# MKW20Z4 register map
Vendor: Freescale Semiconductor, Inc.; Series: Kinetis_W; File version: 1.6
CPU: CM0PLUS r0p0, little endian, no MPU, no FPU, VTOR, 2 interrupt priority bits
Registers are 32-bit, read-write, reset 0x0 unless marked. A register's access mark holds for its fields unless they carry their own. Offsets are from the block's base; [hi:lo] are bit positions; lines under a group give offsets from that group; {n}, {i} and the like mark numbered series.

## XCVR (part 2 of 2) — Apache 1.0 Transceiver
Base 0x4005C000; register names take the prefix XCVR_
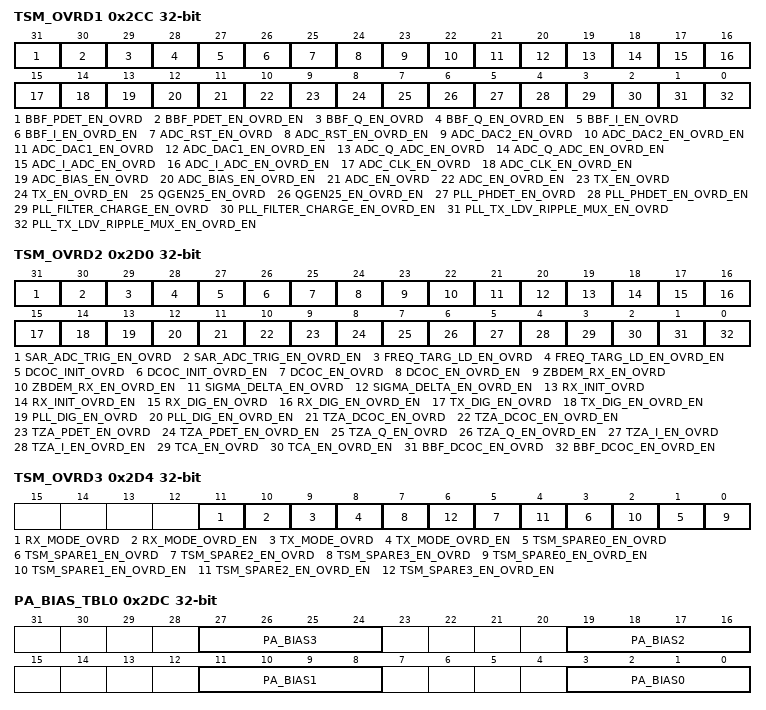
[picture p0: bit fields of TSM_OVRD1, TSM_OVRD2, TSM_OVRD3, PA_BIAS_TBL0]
0x2CC TSM_OVRD1 — TSM Override 1
  [31] BBF_PDET_EN_OVRD — Override value for BBF_PDET_EN
  [30] BBF_PDET_EN_OVRD_EN — Override control for BBF_PDET_EN
    0=Normal operation; 1=Use the state of BBF_PDET_EN_OVRD to override the signal "bbf_pdet_en"
  [29] BBF_Q_EN_OVRD — Override value for BBF_Q_EN
  [28] BBF_Q_EN_OVRD_EN — Override control for BBF_Q_EN
    0=Normal operation; 1=Use the state of BBF_Q_EN_OVRD to override the signal "bbf_q_en"
  [27] BBF_I_EN_OVRD — Override value for BBF_I_EN
  [26] BBF_I_EN_OVRD_EN — Override control for BBF_I_EN
    0=Normal operation; 1=Use the state of BBF_I_EN_OVRD to override the signal "bbf_i_en"
  [25] ADC_RST_EN_OVRD — Override value for ADC_RST_EN
  [24] ADC_RST_EN_OVRD_EN — Override control for ADC_RST_EN
    0=Normal operation; 1=Use the state of ADC_RST_EN_OVRD to override the signal "adc_rst_en"
  [23] ADC_DAC2_EN_OVRD — Override value for ADC_DAC2_EN
  [22] ADC_DAC2_EN_OVRD_EN — Override control for ADC_DAC2_EN
    0=Normal operation; 1=Use the state of ADC_DAC2_EN_OVRD to override the signal "adc_dac2_en"
  [21] ADC_DAC1_EN_OVRD — Override value for ADC_DAC1_EN
  [20] ADC_DAC1_EN_OVRD_EN — Override control for ADC_DAC1_EN
    0=Normal operation; 1=Use the state of ADC_DAC1_EN_OVRD to override the signal "adc_dac1_en"
  [19] ADC_Q_ADC_EN_OVRD — Override value for ADC_Q_ADC_EN
  [18] ADC_Q_ADC_EN_OVRD_EN — Override control for ADC_Q_ADC_EN
    0=Normal operation; 1=Use the state of ADC_Q_ADC_EN_OVRD to override the signal "adc_q_adc_en"
  [17] ADC_I_ADC_EN_OVRD — Override value for ADC_I_ADC_EN
  [16] ADC_I_ADC_EN_OVRD_EN — Override control for ADC_I_ADC_EN
    0=Normal operation; 1=Use the state of ADC_I_ADC_EN_OVRD to override the signal "adc_i_adc_en"
  [15] ADC_CLK_EN_OVRD — Override value for ADC_CLK_EN
  [14] ADC_CLK_EN_OVRD_EN — Override control for ADC_CLK_EN
    0=Normal operation; 1=Use the state of ADC_CLK_EN_OVRD to override the signal "adc_clk_en"
  [13] ADC_BIAS_EN_OVRD — Override value for ADC_BIAS_EN
  [12] ADC_BIAS_EN_OVRD_EN — Override control for ADC_BIAS_EN
    0=Normal operation; 1=Use the state of ADC_BIAS_EN_OVRD to override the signal "adc_bias_en"
  [11] ADC_EN_OVRD — Override value for ADC_EN
  [10] ADC_EN_OVRD_EN — Override control for ADC_EN
    0=Normal operation; 1=Use the state of ADC_EN_OVRD to override the signal "adc_en"
  [9] TX_EN_OVRD — Override value for TX_EN
  [8] TX_EN_OVRD_EN — Override control for TX_EN
    0=Normal operation; 1=Use the state of TX_EN_OVRD to override the signal "tx_en"
  [7] QGEN25_EN_OVRD — Override value for QGEN25_EN
  [6] QGEN25_EN_OVRD_EN — Override control for QGEN25_EN
    0=Normal operation; 1=Use the state of QGEN25_EN_OVRD to override the signal "qgen25_en"
  [5] PLL_PHDET_EN_OVRD — Override value for PLL_PHDET_EN
  [4] PLL_PHDET_EN_OVRD_EN — Override control for PLL_PHDET_EN
    0=Normal operation; 1=Use the state of PLL_PHDET_EN_OVRD to override the signal "pll_phdet_en"
  [3] PLL_FILTER_CHARGE_EN_OVRD — Override value for PLL_FILTER_CHARGE_EN
  [2] PLL_FILTER_CHARGE_EN_OVRD_EN — Override control for PLL_FILTER_CHARGE_EN
    0=Normal operation; 1=Use the state of PLL_FILTER_CHARGE_EN_OVRD to override the signal "pll_filter_charge_en"
  [1] PLL_TX_LDV_RIPPLE_MUX_EN_OVRD — Override value for PLL_TX_LDV_RIPPLE_MUX_EN
  [0] PLL_TX_LDV_RIPPLE_MUX_EN_OVRD_EN — Override control for PLL_TX_LDV_RIPPLE_MUX_EN
    0=Normal operation; 1=Use the state of PLL_TX_LDV_RIPPLE_MUX_EN_OVRD to override the signal "pll_tx_ldv_ripple_mux_en"
0x2D0 TSM_OVRD2 — TSM Override 2
  [31] SAR_ADC_TRIG_EN_OVRD — Override value for SAR_ADC_TRIG_EN
  [30] SAR_ADC_TRIG_EN_OVRD_EN — Override control for SAR_ADC_TRIG_EN
    0=Normal operation; 1=Use the state of SAR_ADC_TRIG_EN_OVRD to override the signal "sar_adc_trig_en"
  [29] FREQ_TARG_LD_EN_OVRD — Override value for FREQ_TARG_LD_EN
  [28] FREQ_TARG_LD_EN_OVRD_EN — Override control for FREQ_TARG_LD_EN
    0=Normal operation; 1=Use the state of FREQ_TARG_LD_EN_OVRD to override the signal "freq_targ_ld_en"
  [27] DCOC_INIT_OVRD — Override value for DCOC_INIT
  [26] DCOC_INIT_OVRD_EN — Override control for DCOC_INIT
    0=Normal operation; 1=Use the state of DCOC_INIT_OVRD to override the signal "dcoc_init"
  [25] DCOC_EN_OVRD — Override value for DCOC_EN
  [24] DCOC_EN_OVRD_EN — Override control for DCOC_EN
    0=Normal operation; 1=Use the state of DCOC_EN_OVRD to override the signal "dcoc_en"
  [23] ZBDEM_RX_EN_OVRD — Override value for ZBDEM_RX_EN
  [22] ZBDEM_RX_EN_OVRD_EN — Override control for ZBDEM_RX_EN
    0=Normal operation; 1=Use the state of ZBDEM_RX_EN_OVRD to override the signal "zbdem_rx_en"
  [21] SIGMA_DELTA_EN_OVRD — Override value for SIGMA_DELTA_EN
  [20] SIGMA_DELTA_EN_OVRD_EN — Override control for SIGMA_DELTA_EN
    0=Normal operation; 1=Use the state of SIGMA_DELTA_EN_OVRD to override the signal "sigma_delta_en"
  [19] RX_INIT_OVRD — Override value for RX_INIT
  [18] RX_INIT_OVRD_EN — Override control for RX_INIT
    0=Normal operation; 1=Use the state of RX_INIT_OVRD to override the signal "rx_init"
  [17] RX_DIG_EN_OVRD — Override value for RX_DIG_EN
  [16] RX_DIG_EN_OVRD_EN — Override control for RX_DIG_EN
    0=Normal operation; 1=Use the state of RX_DIG_EN_OVRD to override the signal "rx_dig_en"
  [15] TX_DIG_EN_OVRD — Override value for TX_DIG_EN
  [14] TX_DIG_EN_OVRD_EN — Override control for TX_DIG_EN
    0=Normal operation; 1=Use the state of TX_DIG_EN_OVRD to override the signal "tx_dig_en"
  [13] PLL_DIG_EN_OVRD — Override value for PLL_DIG_EN
  [12] PLL_DIG_EN_OVRD_EN — Override control for PLL_DIG_EN
    0=Normal operation; 1=Use the state of PLL_DIG_EN_OVRD to override the signal "pll_dig_en"
  [11] TZA_DCOC_EN_OVRD — Override value for TZA_DCOC_EN
  [10] TZA_DCOC_EN_OVRD_EN — Override control for TZA_DCOC_EN
    0=Normal operation; 1=Use the state of TZA_DCOC_EN_OVRD to override the signal "tza_dcoc_en"
  [9] TZA_PDET_EN_OVRD — Override value for TZA_PDET_EN
  [8] TZA_PDET_EN_OVRD_EN — Override control for TZA_PDET_EN
    0=Normal operation; 1=Use the state of TZA_PDET_EN_OVRD to override the signal "tza_pdet_en"
  [7] TZA_Q_EN_OVRD — Override value for TZA_Q_EN
  [6] TZA_Q_EN_OVRD_EN — Override control for TZA_Q_EN
    0=Normal operation; 1=Use the state of TZA_Q_EN_OVRD to override the signal "tza_q_en"
  [5] TZA_I_EN_OVRD — Override value for TZA_I_EN
  [4] TZA_I_EN_OVRD_EN — Override control for TZA_I_EN
    0=Normal operation; 1=Use the state of TZA_I_EN_OVRD to override the signal "tza_i_en"
  [3] TCA_EN_OVRD — Override value for TCA_EN
  [2] TCA_EN_OVRD_EN — Override control for TCA_EN
    0=Normal operation; 1=Use the state of TCA_EN_OVRD to override the signal "tca_en"
  [1] BBF_DCOC_EN_OVRD — Override value for BBF_DCOC_EN
  [0] BBF_DCOC_EN_OVRD_EN — Override control for BBF_DCOC_EN
    0=Normal operation; 1=Use the state of BBF_DCOC_EN_OVRD to override the signal "bbf_dcoc_en"
0x2D4 TSM_OVRD3 — TSM Override 3
  [11] RX_MODE_OVRD — Override value for RX_MODE
  [10] RX_MODE_OVRD_EN — Override control for RX_MODE
    0=Normal operation; 1=Use the state of RX_MODE_OVRD to override the signal "rx_mode"
  [9] TX_MODE_OVRD — Override value for TX_MODE
  [8] TX_MODE_OVRD_EN — Override control for TX_MODE
    0=Normal operation; 1=Use the state of TX_MODE_OVRD to override the signal "tx_mode"
  [2n+1] TSM_SPARE{n}_EN_OVRD (n=0..3) — Override value for TSM_SPARE{n}_EN
  [2n] TSM_SPARE{n}_EN_OVRD_EN (n=0..3) — Override control for TSM_SPARE{n}_EN
    0=Normal operation; 1=Use the state of TSM_SPARE{n}_EN_OVRD to override the signal "tsm_spare{n}_en"
0x2D8 PA_POWER
  [3:0] PA_POWER
0x2DC PA_BIAS_TBL0 — PA Bias Table 0
  [8n+3:8n] PA_BIAS{n} (n=0..3)
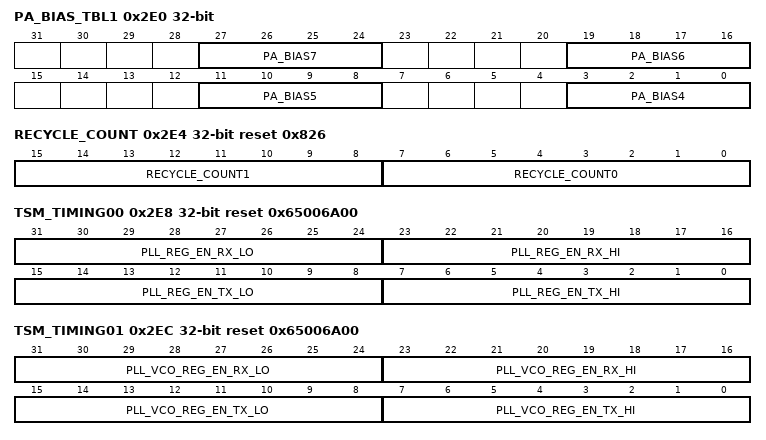
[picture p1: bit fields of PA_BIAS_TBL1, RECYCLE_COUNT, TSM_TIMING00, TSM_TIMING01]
0x2E0 PA_BIAS_TBL1 — PA Bias Table 1
  [8n-29:8n-32] PA_BIAS{n} (n=4..7)
0x2E4 RECYCLE_COUNT reset 0x826
  [15:8] RECYCLE_COUNT1 — TSM RX Recycle Count 1
  [7:0] RECYCLE_COUNT0 — TSM RX Recycle Count 0
0x2E8 TSM_TIMING00 reset 0x65006A00
  [31:24] PLL_REG_EN_RX_LO — Deassertion time setting for PLL_REG_EN signal or group RX sequence.
  [23:16] PLL_REG_EN_RX_HI — Assertion time setting for PLL_REG_EN signal or group RX sequence.
  [15:8] PLL_REG_EN_TX_LO — Deassertion time setting for PLL_REG_EN signal or group TX sequence.
  [7:0] PLL_REG_EN_TX_HI — Assertion time setting for PLL_REG_EN TX sequence.
0x2EC TSM_TIMING01 reset 0x65006A00
  [31:24] PLL_VCO_REG_EN_RX_LO — Deassertion time setting for PLL_VCO_REG_EN signal or group RX sequence.
  [23:16] PLL_VCO_REG_EN_RX_HI — Assertion time setting for PLL_VCO_REG_EN signal or group RX sequence.
  [15:8] PLL_VCO_REG_EN_TX_LO — Deassertion time setting for PLL_VCO_REG_EN signal or group TX sequence.
  [7:0] PLL_VCO_REG_EN_TX_HI — Assertion time setting for PLL_VCO_REG_EN TX sequence.
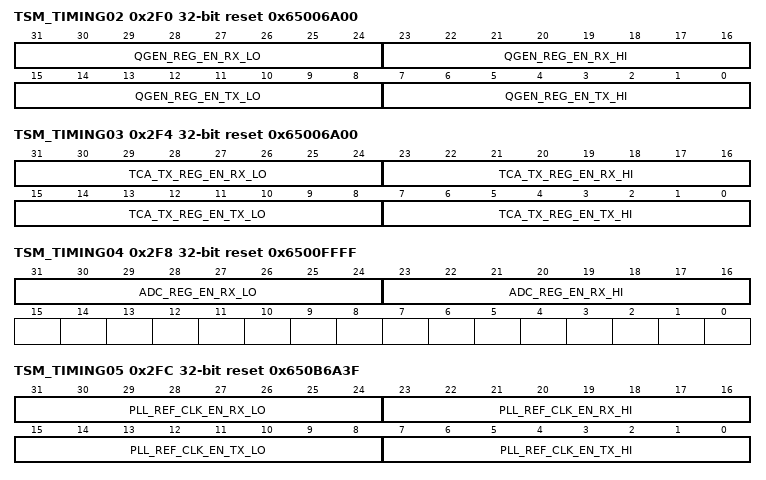
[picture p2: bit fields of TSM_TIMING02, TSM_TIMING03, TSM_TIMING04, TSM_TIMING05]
0x2F0 TSM_TIMING02 reset 0x65006A00
  [31:24] QGEN_REG_EN_RX_LO — Deassertion time setting for QGEN_REG_EN signal or group RX sequence.
  [23:16] QGEN_REG_EN_RX_HI — Assertion time setting for QGEN_REG_EN signal or group RX sequence.
  [15:8] QGEN_REG_EN_TX_LO — Deassertion time setting for QGEN_REG_EN signal or group TX sequence.
  [7:0] QGEN_REG_EN_TX_HI — Assertion time setting for QGEN_REG_EN TX sequence.
0x2F4 TSM_TIMING03 reset 0x65006A00
  [31:24] TCA_TX_REG_EN_RX_LO — Deassertion time setting for TCA_TX_REG_EN signal or group RX sequence.
  [23:16] TCA_TX_REG_EN_RX_HI — Assertion time setting for TCA_TX_REG_EN signal or group RX sequence.
  [15:8] TCA_TX_REG_EN_TX_LO — Deassertion time setting for TCA_TX_REG_EN signal or group TX sequence.
  [7:0] TCA_TX_REG_EN_TX_HI — Assertion time setting for TCA_TX_REG_EN TX sequence.
0x2F8 TSM_TIMING04 reset 0x6500FFFF
  [31:24] ADC_REG_EN_RX_LO — Deassertion time setting for ADC_REG_EN signal or group RX sequence.
  [23:16] ADC_REG_EN_RX_HI — Assertion time setting for ADC_REG_EN signal or group RX sequence.
0x2FC TSM_TIMING05 reset 0x650B6A3F
  [31:24] PLL_REF_CLK_EN_RX_LO — Deassertion time setting for PLL_REF_CLK_EN signal or group RX sequence.
  [23:16] PLL_REF_CLK_EN_RX_HI — Assertion time setting for PLL_REF_CLK_EN signal or group RX sequence.
  [15:8] PLL_REF_CLK_EN_TX_LO — Deassertion time setting for PLL_REF_CLK_EN signal or group TX sequence.
  [7:0] PLL_REF_CLK_EN_TX_HI — Assertion time setting for PLL_REF_CLK_EN TX sequence.
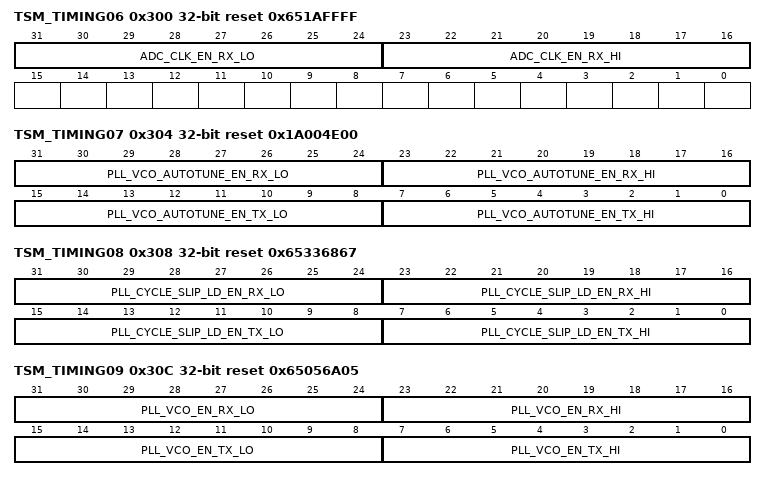
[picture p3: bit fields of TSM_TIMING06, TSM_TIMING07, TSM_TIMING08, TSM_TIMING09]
0x300 TSM_TIMING06 reset 0x651AFFFF
  [31:24] ADC_CLK_EN_RX_LO — Deassertion time setting for ADC_CLK_EN signal or group RX sequence.
  [23:16] ADC_CLK_EN_RX_HI — Assertion time setting for ADC_CLK_EN signal or group RX sequence.
0x304 TSM_TIMING07 reset 0x1A004E00
  [31:24] PLL_VCO_AUTOTUNE_EN_RX_LO — Deassertion time setting for PLL_VCO_AUTOTUNE_EN signal or group RX sequence.
  [23:16] PLL_VCO_AUTOTUNE_EN_RX_HI — Assertion time setting for PLL_VCO_AUTOTUNE_EN signal or group RX sequence.
  [15:8] PLL_VCO_AUTOTUNE_EN_TX_LO — Deassertion time setting for PLL_VCO_AUTOTUNE_EN signal or group TX sequence.
  [7:0] PLL_VCO_AUTOTUNE_EN_TX_HI — Assertion time setting for PLL_VCO_AUTOTUNE_EN TX sequence.
0x308 TSM_TIMING08 reset 0x65336867
  [31:24] PLL_CYCLE_SLIP_LD_EN_RX_LO — Deassertion time setting for PLL_CYCLE_SLIP_LD_EN signal or group RX sequence.
  [23:16] PLL_CYCLE_SLIP_LD_EN_RX_HI — Assertion time setting for PLL_CYCLE_SLIP_LD_EN signal or group RX sequence.
  [15:8] PLL_CYCLE_SLIP_LD_EN_TX_LO — Deassertion time setting for PLL_CYCLE_SLIP_LD_EN signal or group TX sequence.
  [7:0] PLL_CYCLE_SLIP_LD_EN_TX_HI — Assertion time setting for PLL_CYCLE_SLIP_LD_EN TX sequence.
0x30C TSM_TIMING09 reset 0x65056A05
  [31:24] PLL_VCO_EN_RX_LO — Deassertion time setting for PLL_VCO_EN signal or group RX sequence.
  [23:16] PLL_VCO_EN_RX_HI — Assertion time setting for PLL_VCO_EN signal or group RX sequence.
  [15:8] PLL_VCO_EN_TX_LO — Deassertion time setting for PLL_VCO_EN signal or group TX sequence.
  [7:0] PLL_VCO_EN_TX_HI — Assertion time setting for PLL_VCO_EN TX sequence.
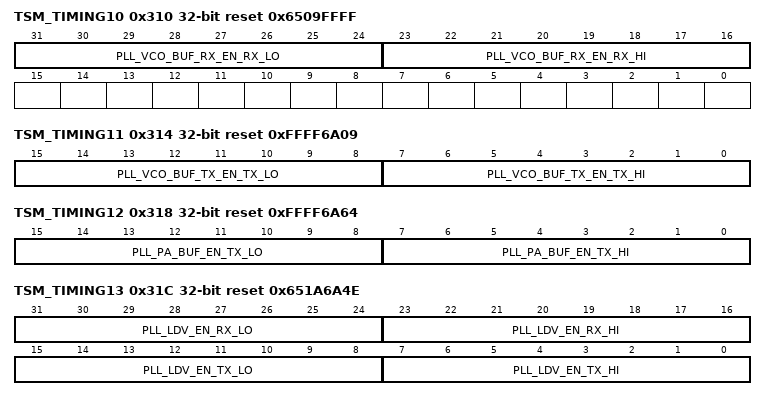
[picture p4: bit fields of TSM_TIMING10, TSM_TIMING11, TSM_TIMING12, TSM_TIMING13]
0x310 TSM_TIMING10 reset 0x6509FFFF
  [31:24] PLL_VCO_BUF_RX_EN_RX_LO — Deassertion time setting for PLL_VCO_BUF_RX_EN signal or group RX sequence.
  [23:16] PLL_VCO_BUF_RX_EN_RX_HI — Assertion time setting for PLL_VCO_BUF_RX_EN signal or group RX sequence.
0x314 TSM_TIMING11 reset 0xFFFF6A09
  [15:8] PLL_VCO_BUF_TX_EN_TX_LO — Deassertion time setting for PLL_VCO_BUF_TX_EN signal or group TX sequence.
  [7:0] PLL_VCO_BUF_TX_EN_TX_HI — Assertion time setting for PLL_VCO_BUF_TX_EN TX sequence.
0x318 TSM_TIMING12 reset 0xFFFF6A64
  [15:8] PLL_PA_BUF_EN_TX_LO — Deassertion time setting for PLL_PA_BUF_EN signal or group TX sequence.
  [7:0] PLL_PA_BUF_EN_TX_HI — Assertion time setting for PLL_PA_BUF_EN TX sequence.
0x31C TSM_TIMING13 reset 0x651A6A4E
  [31:24] PLL_LDV_EN_RX_LO — Deassertion time setting for PLL_LDV_EN signal or group RX sequence.
  [23:16] PLL_LDV_EN_RX_HI — Assertion time setting for PLL_LDV_EN signal or group RX sequence.
  [15:8] PLL_LDV_EN_TX_LO — Deassertion time setting for PLL_LDV_EN signal or group TX sequence.
  [7:0] PLL_LDV_EN_TX_HI — Assertion time setting for PLL_LDV_EN TX sequence.
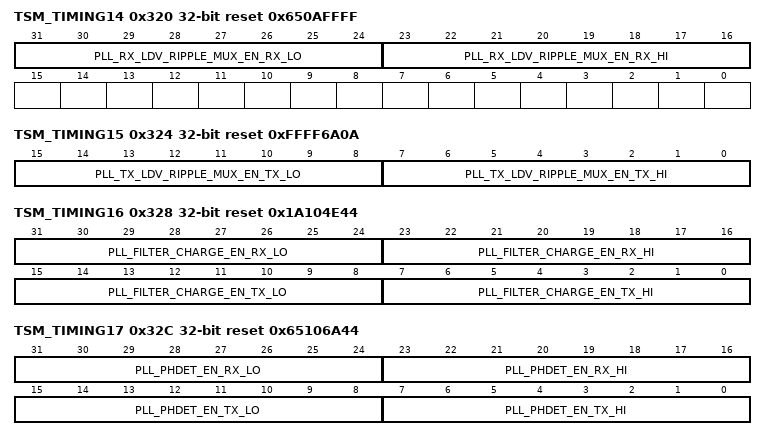
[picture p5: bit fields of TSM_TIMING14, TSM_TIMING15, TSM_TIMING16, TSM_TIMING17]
0x320 TSM_TIMING14 reset 0x650AFFFF
  [31:24] PLL_RX_LDV_RIPPLE_MUX_EN_RX_LO — Deassertion time setting for PLL_RX_LDV_RIPPLE_MUX_EN signal or group RX sequence.
  [23:16] PLL_RX_LDV_RIPPLE_MUX_EN_RX_HI — Assertion time setting for PLL_RX_LDV_RIPPLE_MUX_EN signal or group RX sequence.
0x324 TSM_TIMING15 reset 0xFFFF6A0A
  [15:8] PLL_TX_LDV_RIPPLE_MUX_EN_TX_LO — Deassertion time setting for PLL_TX_LDV_RIPPLE_MUX_EN signal or group TX sequence.
  [7:0] PLL_TX_LDV_RIPPLE_MUX_EN_TX_HI — Assertion time setting for PLL_TX_LDV_RIPPLE_MUX_EN TX sequence.
0x328 TSM_TIMING16 reset 0x1A104E44
  [31:24] PLL_FILTER_CHARGE_EN_RX_LO — Deassertion time setting for PLL_FILTER_CHARGE_EN signal or group RX sequence.
  [23:16] PLL_FILTER_CHARGE_EN_RX_HI — Assertion time setting for PLL_FILTER_CHARGE_EN signal or group RX sequence.
  [15:8] PLL_FILTER_CHARGE_EN_TX_LO — Deassertion time setting for PLL_FILTER_CHARGE_EN signal or group TX sequence.
  [7:0] PLL_FILTER_CHARGE_EN_TX_HI — Assertion time setting for PLL_FILTER_CHARGE_EN TX sequence.
0x32C TSM_TIMING17 reset 0x65106A44
  [31:24] PLL_PHDET_EN_RX_LO — Deassertion time setting for PLL_PHDET_EN signal or group RX sequence.
  [23:16] PLL_PHDET_EN_RX_HI — Assertion time setting for PLL_PHDET_EN signal or group RX sequence.
  [15:8] PLL_PHDET_EN_TX_LO — Deassertion time setting for PLL_PHDET_EN signal or group TX sequence.
  [7:0] PLL_PHDET_EN_TX_HI — Assertion time setting for PLL_PHDET_EN TX sequence.
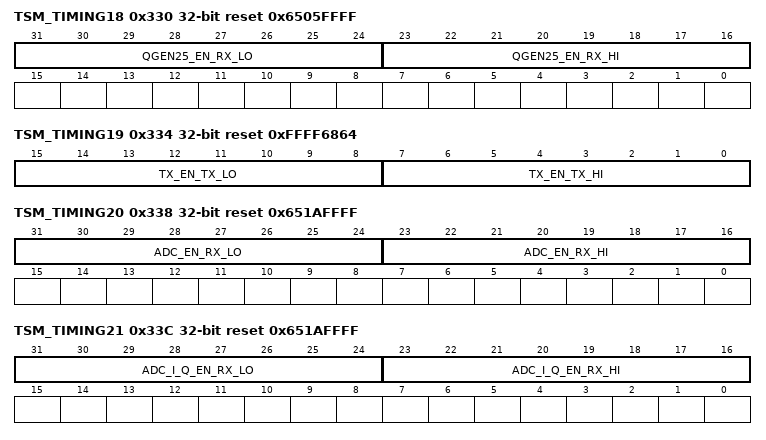
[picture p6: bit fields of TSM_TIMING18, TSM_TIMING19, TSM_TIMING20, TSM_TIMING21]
0x330 TSM_TIMING18 reset 0x6505FFFF
  [31:24] QGEN25_EN_RX_LO — Deassertion time setting for QGEN25_EN signal or group RX sequence.
  [23:16] QGEN25_EN_RX_HI — Assertion time setting for QGEN25_EN signal or group RX sequence.
0x334 TSM_TIMING19 reset 0xFFFF6864
  [15:8] TX_EN_TX_LO — Deassertion time setting for TX_EN signal or group TX sequence.
  [7:0] TX_EN_TX_HI — Assertion time setting for TX_EN TX sequence.
0x338 TSM_TIMING20 reset 0x651AFFFF
  [31:24] ADC_EN_RX_LO — Deassertion time setting for ADC_EN signal or group RX sequence.
  [23:16] ADC_EN_RX_HI — Assertion time setting for ADC_EN signal or group RX sequence.
0x33C TSM_TIMING21 reset 0x651AFFFF
  [31:24] ADC_I_Q_EN_RX_LO — Deassertion time setting for ADC_I_Q_EN signal or group RX sequence.
  [23:16] ADC_I_Q_EN_RX_HI — Assertion time setting for ADC_I_Q_EN signal or group RX sequence.
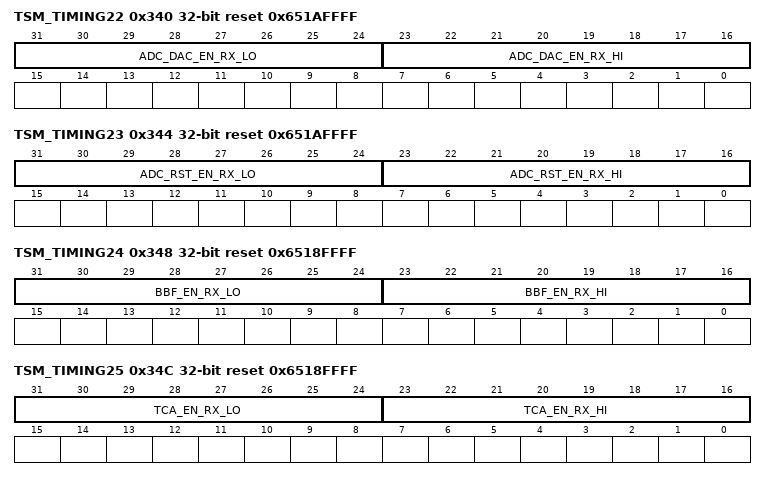
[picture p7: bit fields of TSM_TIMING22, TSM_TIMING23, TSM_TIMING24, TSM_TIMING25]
0x340 TSM_TIMING22 reset 0x651AFFFF
  [31:24] ADC_DAC_EN_RX_LO — Deassertion time setting for ADC_DAC_EN signal or group RX sequence.
  [23:16] ADC_DAC_EN_RX_HI — Assertion time setting for ADC_DAC_EN signal or group RX sequence.
0x344 TSM_TIMING23 reset 0x651AFFFF
  [31:24] ADC_RST_EN_RX_LO — Deassertion time setting for ADC_RST_EN signal or group RX sequence.
  [23:16] ADC_RST_EN_RX_HI — Assertion time setting for ADC_RST_EN signal or group RX sequence.
0x348 TSM_TIMING24 reset 0x6518FFFF
  [31:24] BBF_EN_RX_LO — Deassertion time setting for BBF_EN signal or group RX sequence.
  [23:16] BBF_EN_RX_HI — Assertion time setting for BBF_EN signal or group RX sequence.
0x34C TSM_TIMING25 reset 0x6518FFFF
  [31:24] TCA_EN_RX_LO — Deassertion time setting for TCA_EN signal or group RX sequence.
  [23:16] TCA_EN_RX_HI — Assertion time setting for TCA_EN signal or group RX sequence.
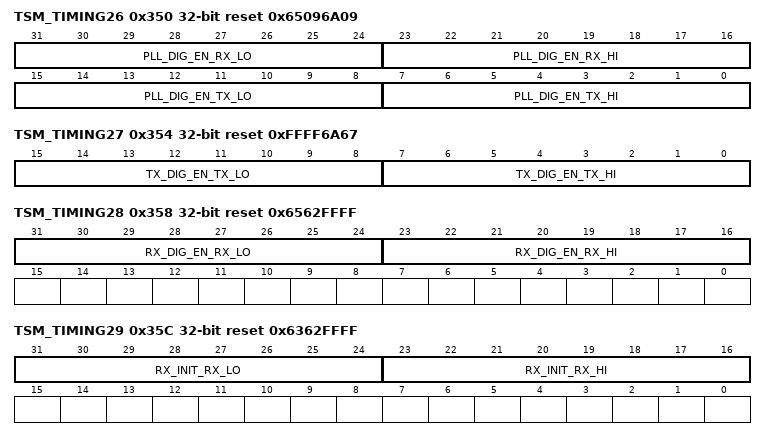
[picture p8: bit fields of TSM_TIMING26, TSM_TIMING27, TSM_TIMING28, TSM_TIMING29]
0x350 TSM_TIMING26 reset 0x65096A09
  [31:24] PLL_DIG_EN_RX_LO — Deassertion time setting for PLL_DIG_EN signal or group RX sequence.
  [23:16] PLL_DIG_EN_RX_HI — Assertion time setting for PLL_DIG_EN signal or group RX sequence.
  [15:8] PLL_DIG_EN_TX_LO — Deassertion time setting for PLL_DIG_EN signal or group TX sequence.
  [7:0] PLL_DIG_EN_TX_HI — Assertion time setting for PLL_DIG_EN TX sequence.
0x354 TSM_TIMING27 reset 0xFFFF6A67
  [15:8] TX_DIG_EN_TX_LO — Deassertion time setting for TX_DIG_EN signal or group TX sequence.
  [7:0] TX_DIG_EN_TX_HI — Assertion time setting for TX_DIG_EN TX sequence.
0x358 TSM_TIMING28 reset 0x6562FFFF
  [31:24] RX_DIG_EN_RX_LO — Deassertion time setting for RX_DIG_EN signal or group RX sequence.
  [23:16] RX_DIG_EN_RX_HI — Assertion time setting for RX_DIG_EN signal or group RX sequence.
0x35C TSM_TIMING29 reset 0x6362FFFF
  [31:24] RX_INIT_RX_LO — Deassertion time setting for RX_INIT signal or group RX sequence.
  [23:16] RX_INIT_RX_HI — Assertion time setting for RX_INIT signal or group RX sequence.
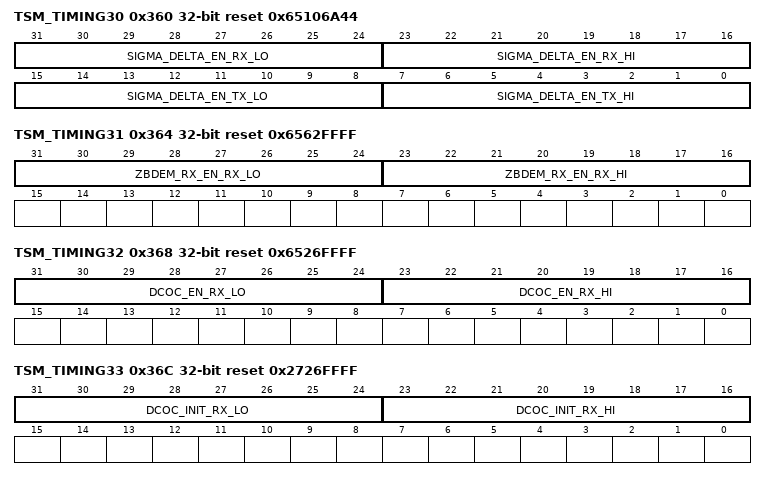
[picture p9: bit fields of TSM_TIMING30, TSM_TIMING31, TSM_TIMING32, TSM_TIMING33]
0x360 TSM_TIMING30 reset 0x65106A44
  [31:24] SIGMA_DELTA_EN_RX_LO — Deassertion time setting for SIGMA_DELTA_EN signal or group RX sequence.
  [23:16] SIGMA_DELTA_EN_RX_HI — Assertion time setting for SIGMA_DELTA_EN signal or group RX sequence.
  [15:8] SIGMA_DELTA_EN_TX_LO — Deassertion time setting for SIGMA_DELTA_EN signal or group TX sequence.
  [7:0] SIGMA_DELTA_EN_TX_HI — Assertion time setting for SIGMA_DELTA_EN TX sequence.
0x364 TSM_TIMING31 reset 0x6562FFFF
  [31:24] ZBDEM_RX_EN_RX_LO — Deassertion time setting for ZBDEM_RX_EN signal or group RX sequence.
  [23:16] ZBDEM_RX_EN_RX_HI — Assertion time setting for ZBDEM_RX_EN signal or group RX sequence.
0x368 TSM_TIMING32 reset 0x6526FFFF
  [31:24] DCOC_EN_RX_LO — Deassertion time setting for DCOC_EN signal or group RX sequence.
  [23:16] DCOC_EN_RX_HI — Assertion time setting for DCOC_EN signal or group RX sequence.
0x36C TSM_TIMING33 reset 0x2726FFFF
  [31:24] DCOC_INIT_RX_LO — Deassertion time setting for DCOC_INIT signal or group RX sequence.
  [23:16] DCOC_INIT_RX_HI — Assertion time setting for DCOC_INIT signal or group RX sequence.
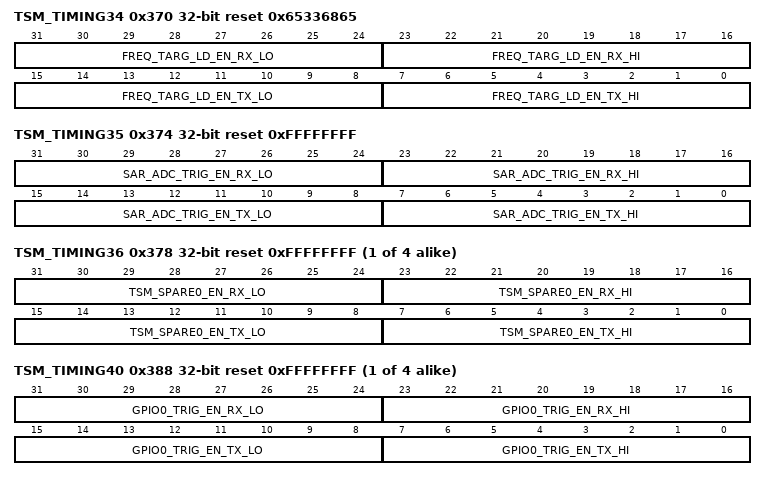
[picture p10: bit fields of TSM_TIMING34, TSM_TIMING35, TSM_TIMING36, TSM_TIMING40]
0x370 TSM_TIMING34 reset 0x65336865
  [31:24] FREQ_TARG_LD_EN_RX_LO — Deassertion time setting for FREQ_TARG_LD_EN signal or group RX sequence.
  [23:16] FREQ_TARG_LD_EN_RX_HI — Assertion time setting for FREQ_TARG_LD_EN signal or group RX sequence.
  [15:8] FREQ_TARG_LD_EN_TX_LO — Deassertion time setting for FREQ_TARG_LD_EN signal or group TX sequence.
  [7:0] FREQ_TARG_LD_EN_TX_HI — Assertion time setting for FREQ_TARG_LD_EN TX sequence.
0x374 TSM_TIMING35 reset 0xFFFFFFFF
  [31:24] SAR_ADC_TRIG_EN_RX_LO — Deassertion time setting for SAR_ADC_TRIG_EN signal or group RX sequence.
  [23:16] SAR_ADC_TRIG_EN_RX_HI — Assertion time setting for SAR_ADC_TRIG_EN signal or group RX sequence.
  [15:8] SAR_ADC_TRIG_EN_TX_LO — Deassertion time setting for SAR_ADC_TRIG_EN signal or group TX sequence.
  [7:0] SAR_ADC_TRIG_EN_TX_HI — Assertion time setting for SAR_ADC_TRIG_EN TX sequence.
{0x2E8+4i} TSM_TIMING{i} reset 0xFFFFFFFF (i=36..39)
  [31:24] TSM_SPARE{i-36}_EN_RX_LO — Deassertion time setting for TSM_SPARE{i-36}_EN signal or group RX sequence.
  [23:16] TSM_SPARE{i-36}_EN_RX_HI — Assertion time setting for TSM_SPARE{i-36}_EN signal or group RX sequence.
  [15:8] TSM_SPARE{i-36}_EN_TX_LO — Deassertion time setting for TSM_SPARE{i-36}_EN signal or group TX sequence.
  [7:0] TSM_SPARE{i-36}_EN_TX_HI — Assertion time setting for TSM_SPARE{i-36}_EN TX sequence.
{0x2E8+4i} TSM_TIMING{i} reset 0xFFFFFFFF (i=40..43)
  [31:24] GPIO{i-40}_TRIG_EN_RX_LO — Deassertion time setting for GPIO{i-40}_TRIG_EN signal or group RX sequence.
  [23:16] GPIO{i-40}_TRIG_EN_RX_HI — Assertion time setting for GPIO{i-40}_TRIG_EN signal or group RX sequence.
  [15:8] GPIO{i-40}_TRIG_EN_TX_LO — Deassertion time setting for GPIO{i-40}_TRIG_EN signal or group TX sequence.
  [7:0] GPIO{i-40}_TRIG_EN_TX_HI — Assertion time setting for GPIO{i-40}_TRIG_EN TX sequence.
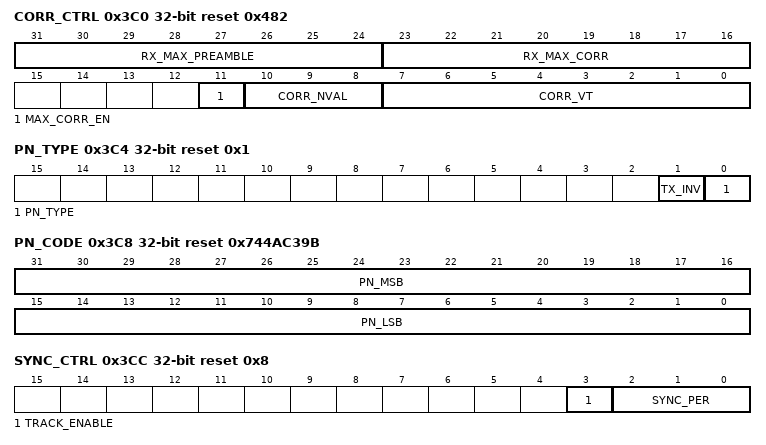
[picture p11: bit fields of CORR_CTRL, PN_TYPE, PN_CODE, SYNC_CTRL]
0x3C0 CORR_CTRL reset 0x482
  [31:24] RX_MAX_PREAMBLE ro, [23:16] RX_MAX_CORR ro, [11] MAX_CORR_EN, [10:8] CORR_NVAL, [7:0] CORR_VT
0x3C4 PN_TYPE reset 0x1
  [1] TX_INV, [0] PN_TYPE
0x3C8 PN_CODE reset 0x744AC39B
  [31:16] PN_MSB, [15:0] PN_LSB
0x3CC SYNC_CTRL reset 0x8 — Sync Control
  [3] TRACK_ENABLE
    0=symbol timing synchronization tracking disabled in Rx frontend; 1=symbol timing synchronization tracking enabled in Rx frontend (default)
  [2:0] SYNC_PER — Symbol Sync Tracking Period
0x3D0 SNF_THR
  [7:0] SNF_THR — SNIFF Mode Threshold
0x3D4 FAD_THR reset 0x82
  [7:0] FAD_THR
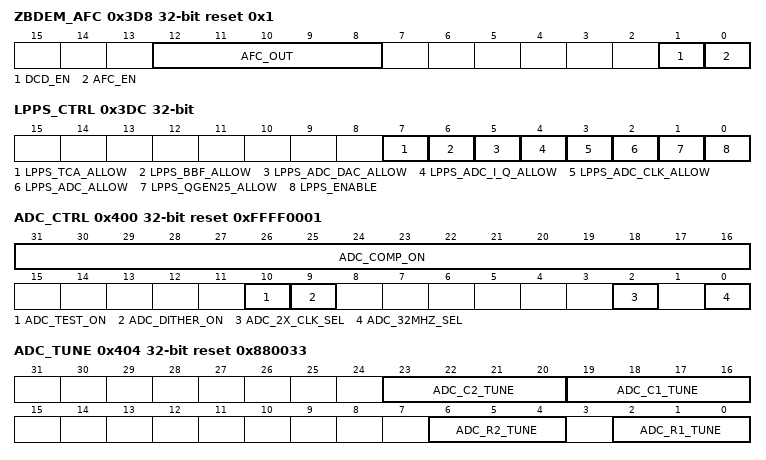
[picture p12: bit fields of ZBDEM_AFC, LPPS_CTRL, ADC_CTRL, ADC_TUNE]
0x3D8 ZBDEM_AFC reset 0x1
  [12:8] AFC_OUT ro
  [1] DCD_EN — DCD Mode Enable
    0=NCD Mode (default); 1=DCD Mode
  [0] AFC_EN
0x3DC LPPS_CTRL — LPPS Control Register
  [7] LPPS_TCA_ALLOW
    0=Disallow TCA-related TSM outputs {tca_en, tza_i_en, tza_q_en, tza_pdet_en, tza_dcoc_en} to be duty-cycled during LPPS; 1=Allow TCA-related TSM outputs {tca_en, tza_i_en, tza_q_en, tza_pdet_en, tza_dcoc_en} to be duty-cycled during LPPS
  [6] LPPS_BBF_ALLOW
    0=Disallow BBF-related TSM outputs {bbf_i_en, bbf_q_en, bbf_pdet_en, bbf_dcoc_en} to be duty-cycled during LPPS; 1=Allow BBF-related TSM outputs {bbf_i_en, bbf_q_en, bbf_pdet_en, bbf_dcoc_en} to be duty-cycled during LPPS
  [5] LPPS_ADC_DAC_ALLOW
    0=Disallow ADC_DAC-related TSM outputs {adc_dac1_en, adc_dac2_en} to be duty-cycled during LPPS; 1=Allow ADC_DAC-related TSM outputs {adc_dac1_en, adc_dac2_en} to be duty-cycled during LPPS
  [4] LPPS_ADC_I_Q_ALLOW
    0=Disallow ADC_I/Q-related TSM outputs {adc_I_adc_en, adc_Q_adc_en} to be duty-cycled during LPPS; 1=Allow ADC_I/Q-related TSM outputs {adc_I_adc_en, adc_Q_adc_en} to be duty-cycled during LPPS
  [3] LPPS_ADC_CLK_ALLOW
    0=Disallow ADC-related TSM outputs {xtal_adc_ref_clk_en, adc_clk_en} to be duty-cycled during LPPS; 1=Allow ADC_CLK-related TSM outputs {xtal_adc_ref_clk_en, adc_clk_en} to be duty-cycled during LPPS
  [2] LPPS_ADC_ALLOW
    0=Disallow ADC-related TSM outputs {adc_en, adc_bias_en} to be duty-cycled during LPPS; 1=Allow ADC-related TSM outputs {adc_en, adc_bias_en} to be duty-cycled during LPPS
  [1] LPPS_QGEN25_ALLOW
    0=Disallow TSM output qgen25_en to be duty-cycled during LPPS; 1=Allow TSM output qgen25_en to be duty-cycled during LPPS
  [0] LPPS_ENABLE — LPPS Mode Enable
    0=LPPS mode disabled; 1=LPPS mode enabled
0x400 ADC_CTRL reset 0xFFFF0001 — ADC Control
  [31:16] ADC_COMP_ON — ADC Comparator Enable
  [10] ADC_TEST_ON
  [9] ADC_DITHER_ON
  [2] ADC_2X_CLK_SEL
  [0] ADC_32MHZ_SEL — ADC 32MHZ Clock Select
0x404 ADC_TUNE reset 0x880033 — ADC Tuning
  [23:20] ADC_C2_TUNE, [19:16] ADC_C1_TUNE, [6:4] ADC_R2_TUNE, [2:0] ADC_R1_TUNE
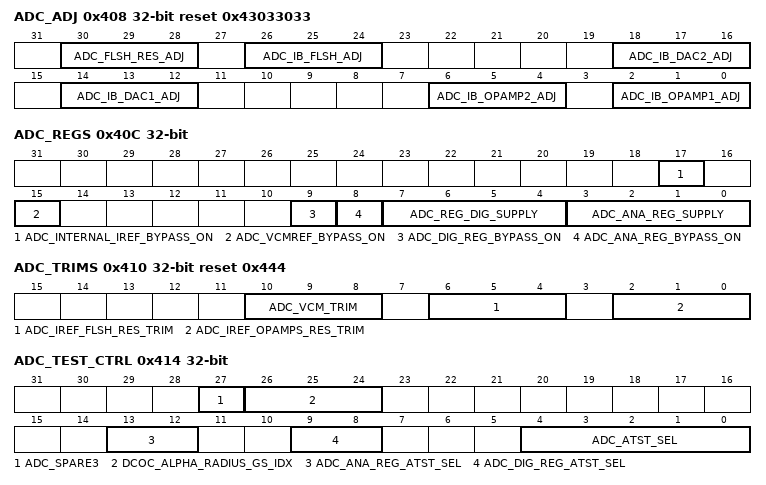
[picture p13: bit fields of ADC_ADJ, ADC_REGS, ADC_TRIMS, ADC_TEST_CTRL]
0x408 ADC_ADJ reset 0x43033033 — ADC Adjustment
  [30:28] ADC_FLSH_RES_ADJ, [26:24] ADC_IB_FLSH_ADJ, [18:16] ADC_IB_DAC2_ADJ, [14:12] ADC_IB_DAC1_ADJ, [6:4] ADC_IB_OPAMP2_ADJ, [2:0] ADC_IB_OPAMP1_ADJ
0x40C ADC_REGS — ADC Regulators
  [17] ADC_INTERNAL_IREF_BYPASS_ON
  [15] ADC_VCMREF_BYPASS_ON
  [9] ADC_DIG_REG_BYPASS_ON
  [8] ADC_ANA_REG_BYPASS_ON
  [7:4] ADC_REG_DIG_SUPPLY
    0=1.2V; 1=1.05V; 2=1.275V; 3=1.3V
  [3:0] ADC_ANA_REG_SUPPLY
    0=1.2V; 1=1.05V; 2=1.275V; 3=1.3V
0x410 ADC_TRIMS reset 0x444 — ADC Regulator Trims
  [10:8] ADC_VCM_TRIM, [6:4] ADC_IREF_FLSH_RES_TRIM, [2:0] ADC_IREF_OPAMPS_RES_TRIM
0x414 ADC_TEST_CTRL — ADC Test Control
  [27] ADC_SPARE3
  [26:24] DCOC_ALPHA_RADIUS_GS_IDX — Alpha-R Scaling
    0=1; 1=1/2; 2=1/4; 3=1/8; 4=1/16; 5=1/32; 6=1/64
  [13:12] ADC_ANA_REG_ATST_SEL
  [9:8] ADC_DIG_REG_ATST_SEL
  [4:0] ADC_ATST_SEL — ADC Analog Test Selection
    0=Inject 5uA refrence current on ATST0 ,Inject 0.6V reference voltage on ATST1; 1=Monitor Flash refrence currents on ATST3
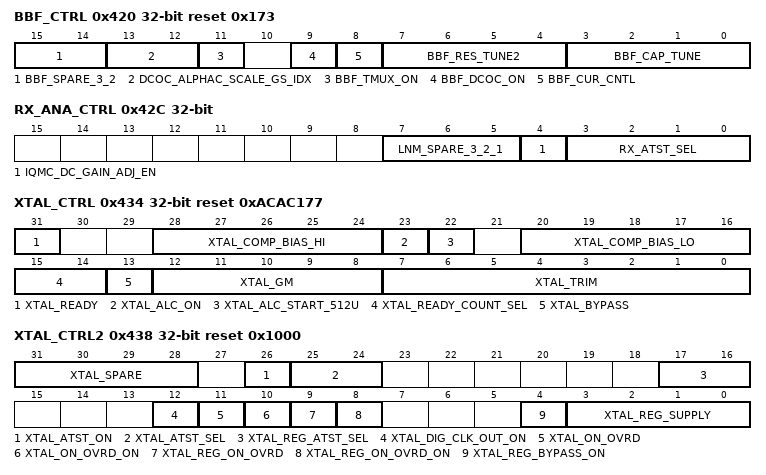
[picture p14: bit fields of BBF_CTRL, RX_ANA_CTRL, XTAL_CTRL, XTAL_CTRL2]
0x420 BBF_CTRL reset 0x173 — Baseband Filter Control
  [15:14] BBF_SPARE_3_2
  [13:12] DCOC_ALPHAC_SCALE_GS_IDX — DCOC Alpha-C Scaling
    0=1/2; 1=1/4; 2=1/8; 3=1/16
  [11] BBF_TMUX_ON
  [9] BBF_DCOC_ON
  [8] BBF_CUR_CNTL
    0=Low current setting; 1=High current setting
  [7:4] BBF_RES_TUNE2
  [3:0] BBF_CAP_TUNE
0x42C RX_ANA_CTRL — RX Analog Control
  [7:5] LNM_SPARE_3_2_1, [4] IQMC_DC_GAIN_ADJ_EN, [3:0] RX_ATST_SEL
0x434 XTAL_CTRL reset 0xACAC177 (reset mask 0x7FFFFFFF) — Crystal Oscillator Control Register 1
  [31] XTAL_READY ro — XTAL Ready Indicator
  [28:24] XTAL_COMP_BIAS_HI — XTAL_COMP_BIAS (High)
  [23] XTAL_ALC_ON
  [22] XTAL_ALC_START_512U
    0=Start XTAL ALC at 256usec; 1=Start XTAL ALC at 512usec
  [20:16] XTAL_COMP_BIAS_LO — XTAL_COMP_BIAS (Low)
  [15:14] XTAL_READY_COUNT_SEL — XTAL Ready Count Select
    0=1024 clock cycles; 1=2048 clock cycles; 2=4096 clock cycles; 3=8192 clock cycles
  [13] XTAL_BYPASS
  [12:8] XTAL_GM
  [7:0] XTAL_TRIM
0x438 XTAL_CTRL2 reset 0x1000 — Crystal Oscillator Control Register 2
  [31:28] XTAL_SPARE
  [26] XTAL_ATST_ON
  [25:24] XTAL_ATST_SEL
  [17:16] XTAL_REG_ATST_SEL
  [12] XTAL_DIG_CLK_OUT_ON
  [11] XTAL_ON_OVRD
  [10] XTAL_ON_OVRD_ON
  [9] XTAL_REG_ON_OVRD
  [8] XTAL_REG_ON_OVRD_ON
  [4] XTAL_REG_BYPASS_ON
  [3:0] XTAL_REG_SUPPLY
    0=1.2V; 1=1.05V; 2=1.275V; 3=1.3V
0x43C BGAP_CTRL reset 0x87 — Bandgap Control
  [12] BGAP_ATST_ON, [11:8] BGAP_ATST_SEL, [7:4] BGAP_VOLTAGE_TRIM, [3:0] BGAP_CURRENT_TRIM
0x444 PLL_CTRL reset 0x23 — PLL Control Register
  [31] PLL_VCO_SPARE7
  [30:24] HPM_BIAS — HPM Array Bias
  [17] PLL_VCO_LDO_BYPASS
  [16] PLL_REG_BYPASS_ON
  [11:8] PLL_REG_SUPPLY
    0=1.2V; 1=1.05V; 2=1.275V; 3=1.3V
  [6:4] PLL_LFILT_CNTL — PLL Loop Filter Control
  [2:0] PLL_VCO_BIAS — PLL VCO Bias Control
0x448 PLL_CTRL2 reset 0x4 — PLL Control Register 2
  [8] PLL_TMUX_ON
  [5:4] PLL_VCO_REG_SUPPLY
    0=1.15V; 1=1.2V
  [3] PLL_KMOD_SLOPE
  [2:0] PLL_VCO_KV
0x44C PLL_TEST_CTRL — PLL Test Control
  [14] PLL_RIPPLE_COUNTER_TEST_MODE, [13] PLL_FORCE_VTUNE_EXTERNALLY, [12] PLL_VCO_TEST_CLK_MODE, [9:8] PLL_REG_ATST_SEL, [5:4] PLL_VCO_REG_ATST, [1:0] PLL_TMUX_SEL
0x458 QGEN_CTRL — QGEN Control
  [8] QGEN_REG_BYPASS_ON
  [7:4] QGEN_REG_ATST_SEL
  [3:0] QGEN_REG_SUPPLY
    0=1.2V; 1=1.05V; 2=1.275V; 3=1.3V
0x464 TCA_CTRL — TCA Control
  [9:8] TCA_TX_REG_ATST_SEL
  [7:4] TCA_TX_REG_SUPPLY
    0=1.2V; 1=1.05V; 2=1.275V; 3=1.3V
  [3] TCA_TX_REG_BYPASS_ON
  [2] TCA_LOW_PWR_ON
  [1:0] TCA_BIAS_CURR
0x468 TZA_CTRL reset 0x44 — TZA Control
  [23:20] TZA_SPARE, [7:6] TZA_CUR_CNTL, [5] TZA_DCOC_ON, [4] TZA_GAIN, [3:0] TZA_CAP_TUNE
0x474 TX_ANA_CTRL — TX Analog Control
  [3:0] HPM_CAL_ADJUST — HPM Cal Count Adjust
0x47C ANA_SPARE — Analog Spare
  [21:16] ANA_DTEST ro
  [15:14] HPM_LSB_INVERT — High port LSB array inversion control
  [13:11] DCOC_TRK_EST_GS_CNT — DCOC Tracking Estimator Gearshift Count
    0=Only use {dcoc_alpha_radius_idx, dcoc_alphac_scaling_idx, dcoc_sign_scaling_idx}; 1=Switch from {dcoc_alpha_radius_idx, dcoc_alphac_scaling_idx, dcoc_sign_scaling_idx} to {dcoc_alpha_radius_gs_idx, dcoc_alphac_scaling_gs_idx, dcoc_sign_scaling_idx} after the 1 update correction
  [10:0] IQMC_DC_GAIN_ADJ — IQ Mismatch Correction DC Gain Coeff
